# IC register map
Vendor: Texas Instruments
Peripheral module from a debugger description file (folder omap34xx).
Registers are 32-bit, read-only, reset 0x0 unless marked. A register's access mark holds for its fields unless they carry their own. Offsets are as the file gives them; lines under a group give offsets from that group; [hi:lo] are bit positions; {n}, {i} and the like mark numbered series; 'fields as' and 'values as' point back to an identical list; <NAME> marks a mode.

## IC
{0x0+4i} EVTFLAGi_{i} (i=0..3) — Event Flag Register
  [31:0] EF — Event Flag status0: No event occurred1: An event occurred
{0x20+4i} EVTSETi_{i} wo (i=0..3) — Event Set Register
  [31:0] ES — Event SetWrite 0: No actionWrite 1: Set corresponding event flag
{0x40+4i} EVTCLRi_{i} wo (i=0..3) — Event Clear Register
  [31:0] EC — Event ClearWrite 0: No actionWrite 1: Clear corresponding event flag
{0x80+4i} EVTMASKi_{i} rw (i=0..3) — Event Mask Register
  [31:0] EM — Disables event from being used as input to the event combiner:0: Will be combined1: Is disabled from being combined.
{0xA0+4i} MEVTFLAGi_{i} (i=0..3) — Masked Event Flag Register
  [31:0] MEF — Masked Event Flag0: No unmasked event occurred1: An unmasked event occurred
{0xC0+4i} EXPMASKi_{i} rw reset 0xFFFFFFFF (i=0..3) — Exception Mask Register 0
  [31:0] XM — Enables event from being used in the exception combiner:0: Will be combined1: Is disabled from being combined
{0xE0+4i} MEXPFLAGi_{i} (i=0..3) — Masked Exception Flag Register 0
  [31:0] MXF — Masked Exception Flag0: No unmasked exception occurred1: An unmasked exception occurred
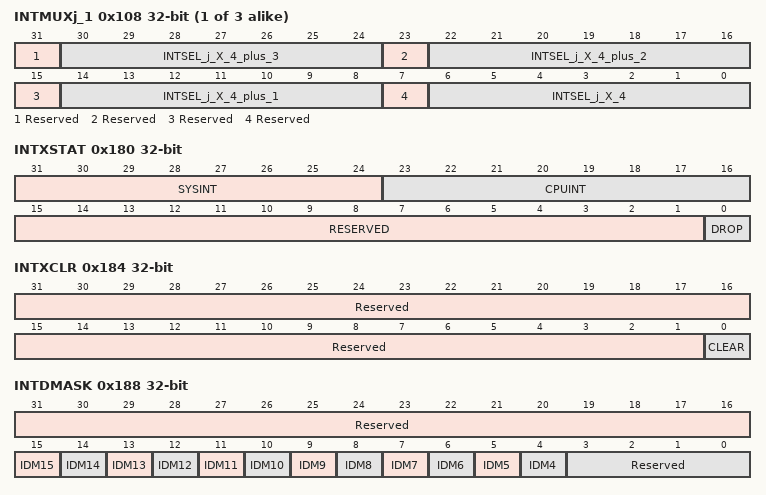
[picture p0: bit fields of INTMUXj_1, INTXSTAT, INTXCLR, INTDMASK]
{0x104+4i} INTMUXj_{i} rw (reset mask 0x80808080) (i=1..3) — Interrupt Mux Register
  [31] Reserved — Write 0s for future compatibility.Read returns 0.
  [30:24] INTSEL_j_X_4_plus_3 — Source event number of the CPU interrupt #j*4+3
  [23] Reserved — Write 0s for future compatibility.Read returns 0.
  [22:16] INTSEL_j_X_4_plus_2 — Source event number of the CPU interrupt #j*4+2
  [15] Reserved — Write 0s for future compatibility.Read returns 0.
  [14:8] INTSEL_j_X_4_plus_1 — Source event number of the CPU interrupt #j*4+1
  [7] Reserved — Write 0s for future compatibility.Read returns 0.
  [6:0] INTSEL_j_X_4 — Source event number of the CPU interrupt #j*4
0x180 INTXSTAT — Interrupt Exception Status Register
  [31:24] SYSINT — System Event number....... . Others: Reserved .
  [23:16] CPUINT — CPU interrupt number....... . Others: Reserved .
  [15:1] RESERVED — Write 0s for future compatibility.Read returns 0.
  [0] DROP — Dropped event flag0: No events dropped1: Event was dropped by the CPU
0x184 INTXCLR wo — Interrupt Exception Clear Register
  [31:1] Reserved — Write 0s for future compatibility.Read returns 0.
  [0] CLEAR — Interrupt exception status clear register:Write 0: No effectWrite 1: Clears the Interrupt Exception Status register
0x188 INTDMASK rw — Dropped Interrupt Mask Register
  [31:16] Reserved — Write 0 for future compatibilityRead returns 0
  [n] IDM{n} (n=4..15) — Dropped event mask for CPU interrupt #{n}
  [3:0] Reserved — Write 0 for future compatibilityRead returns 0
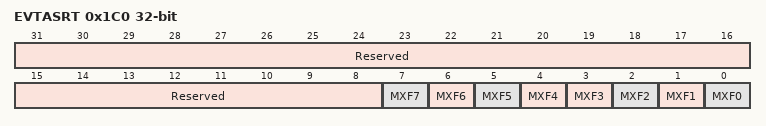
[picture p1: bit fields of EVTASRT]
0x1C0 EVTASRT wo — Event Assert Register
  [31:8] Reserved — write 0 for future compatibility
  [7] MXF7 — Event Assert output #7EA7 = 0: No effect EA7 = 1: EVTOUT7 pulsed high for 4 clk1 cycles, then low.
  [6] MXF6 — Event Assert output #6 EA6 = 0: No effect EA6 = 1: EVTOUT6 pulsed high for 4 clk1 cycles, then low.
  [5] MXF5 — Event Assert output #5EA5 = 0: No effect EA5 = 1: EVTOUT5 pulsed high for 4 clk1 cycles, then low.
  [4] MXF4 — Event Assert output #4 EA4 = 0: No effect EA4 = 1: EVTOUT4 pulsed high for 4 clk1 cycles, then low.
  [n] MXF{n} (n=0..3) — Event Assert output #{n}EA{n} = 0: No effect EA{n} = 1: EVTOUT{n} pulsed high for 4 clk1 cycles, then low.
